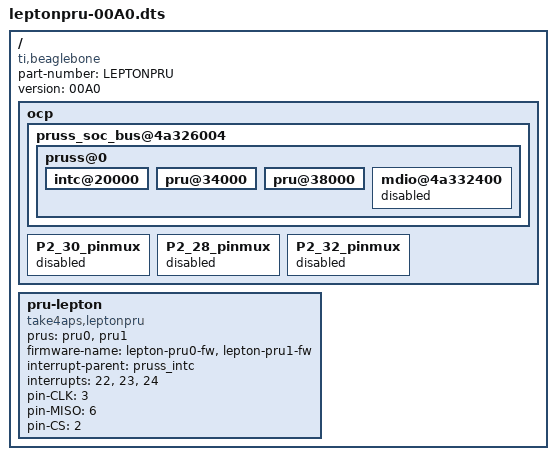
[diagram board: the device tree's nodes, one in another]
/*
 * Copyright (C) 2019-2020 Mikhail Zemlyanukha [gmixaz@gmail.com]
 *
 * This program is free software; you can redistribute it and/or modify
 * it under the terms of the GNU General Public License version 2 as
 * published by the Free Software Foundation.
 */
/dts-v1/;
/plugin/;


/* 
 * On PocketBeagle PRUSS is disabled in DT, so enable it first
 */
 
/ {
	compatible = "ti,beaglebone", "ti,beaglebone-black", "ti,beaglebone-green";

	// identification
	part-number = "AM335X-PRU-RPROC-4-14-TI";
	version = "00A0";

	fragment@0 {
		target-path="/";
		__overlay__ {

			ocp {

				pruss_soc_bus@4a326004 {
					status = "okay";

					pruss@0 {
						status = "okay";

						intc@20000 {
						        status = "okay";
						};

						pru@34000 {
							status = "okay";
						};

						pru@38000 {
							status = "okay";
						};

						mdio@4a332400 {
							status = "disabled";
						};
					};
				};

			};
		};
	};
};

/* 
 * LeptonPRU configuration
 */
/ {
	compatible = "ti,beaglebone", "ti,beaglebone-black", "ti,beaglebone-green";

	// identification
	part-number = "LEPTONPRU";
	version = "00A0";
	fragment@0 {
		target-path="/";
		__overlay__ {
			/* Add default settings */
			pru-lepton {
				compatible = "take4aps,leptonpru";

				prus = <&pru0>, <&pru1>;
				firmware-name = "lepton-pru0-fw", "lepton-pru1-fw";

				interrupt-parent = <&pruss_intc>;
				interrupts = <22>, <23>, <24>;
				interrupt-names = "from_lepton_1", "to_lepton", "from_lepton_2";

				/* pin muxing */
                                pinctrl-names = "default";
                                /* for BBB 
				pinctrl-0 = <&P8_12_pruout_pin &P9_27_pruin_pin &P9_30_pruin_pin>;
				*/
                                /* for PB */
//				pinctrl-0 = <&P2_30_pruout_pin &P2_28_pruin_pin &P2_32_pruin_pin>;
				/**/

				/* pin numbers (of the pins above, used by PRU firmware) */
                                /* for BBB
                                pin-CLK = <14>;
                                pin-MISO = <5>;
                                pin-CS = <2>;
				*/
                                /* for PB */
                                pin-CLK = <3>;
                                pin-MISO = <6>;
                                pin-CS = <2>;
                                /**/
			};
		};
	};


	fragment@1 {
		target-path="/";
		__overlay__ {
/**/
			ocp {
				P2_30_pinmux {
					status = "disabled";
				};
				P2_28_pinmux {
					status = "disabled";
				};
				P2_32_pinmux {
					status = "disabled";
				};
			};
/*
			ocp {
				P8_12_pinmux {
					status = "disabled";
				};
				P9_27_pinmux {
					status = "disabled";
				};
				P9_30_pinmux {
					status = "disabled";
				};
			};
*/
		};
	};


};

